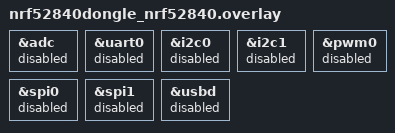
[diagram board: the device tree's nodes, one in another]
/*
 * Copyright (c) 2024 Koen Vervloesem <koen@vervloesem.eu>
 *
 * SPDX-License-Identifier: MIT
 */

/*
 * Disabled unused hardware
 */
&adc {
        status = "disabled";
};
&uart0 {
        status = "disabled";
};
&i2c0 {
        status = "disabled";
};
&i2c1 {
        status = "disabled";
};
&pwm0 {
        status = "disabled";
};
&spi0 {
        status = "disabled";
};
&spi1 {
        status = "disabled";
};
&usbd {
        status = "disabled";
};
